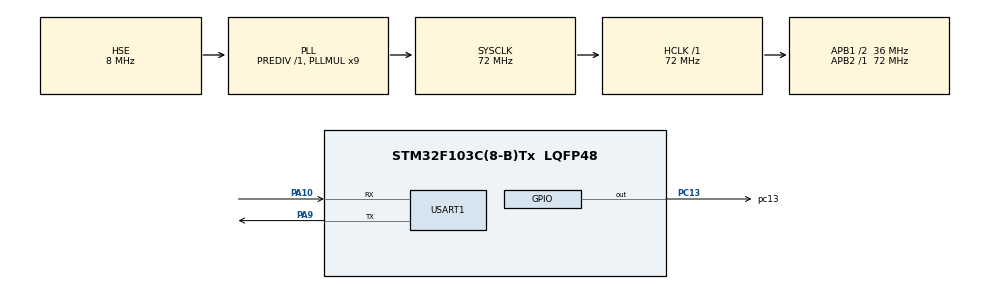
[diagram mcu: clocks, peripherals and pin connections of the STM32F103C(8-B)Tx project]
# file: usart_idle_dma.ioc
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Dma.Request0=USART1_RX
Dma.Request1=USART1_TX
Dma.USART1_RX.0.Direction=DMA_PERIPH_TO_MEMORY
Dma.USART1_RX.0.Instance=DMA1_Channel5
Dma.USART1_RX.0.MemDataAlignment=DMA_MDATAALIGN_BYTE
Dma.USART1_RX.0.MemInc=DMA_MINC_ENABLE
Dma.USART1_RX.0.Mode=DMA_NORMAL
Dma.USART1_RX.0.PeriphDataAlignment=DMA_PDATAALIGN_BYTE
Dma.USART1_RX.0.PeriphInc=DMA_PINC_DISABLE
Dma.USART1_RX.0.Priority=DMA_PRIORITY_LOW
Dma.USART1_TX.1.Direction=DMA_MEMORY_TO_PERIPH
Dma.USART1_TX.1.Instance=DMA1_Channel4
Dma.USART1_TX.1.MemDataAlignment=DMA_MDATAALIGN_BYTE
Dma.USART1_TX.1.MemInc=DMA_MINC_ENABLE
Dma.USART1_TX.1.Mode=DMA_NORMAL
Dma.USART1_TX.1.PeriphDataAlignment=DMA_PDATAALIGN_BYTE
Dma.USART1_TX.1.PeriphInc=DMA_PINC_DISABLE
Dma.USART1_TX.1.Priority=DMA_PRIORITY_LOW
Mcu.Family=STM32F1
Mcu.Name=STM32F103C(8-B)Tx
Mcu.Package=LQFP48
NVIC.DMA1_Channel4_IRQn=true\:0\:0\:false\:false\:true\:false
NVIC.DMA1_Channel5_IRQn=true\:0\:0\:false\:false\:true\:false
NVIC.PriorityGroup=NVIC_PRIORITYGROUP_4
NVIC.USART1_IRQn=true\:0\:0\:false\:false\:true\:true
PA10.Mode=Asynchronous
PA10.Signal=USART1_RX
PA13.Mode=Serial_Wire
PA13.Signal=SYS_JTMS-SWDIO
PA14.Mode=Serial_Wire
PA14.Signal=SYS_JTCK-SWCLK
PA9.Mode=Asynchronous
PA9.Signal=USART1_TX
PC13-TAMPER-RTC.GPIO_Label=pc13
PC13-TAMPER-RTC.Signal=GPIO_Output
PD0-OSC_IN.Mode=HSE-External-Oscillator
PD0-OSC_IN.Signal=RCC_OSC_IN
PD1-OSC_OUT.Mode=HSE-External-Oscillator
PD1-OSC_OUT.Signal=RCC_OSC_OUT
ProjectManager.HeapSize=0x200
ProjectManager.StackSize=0x400
ProjectManager.TargetToolchain=TrueSTUDIO
RCC.AHBFreq_Value=72000000
RCC.APB1CLKDivider=RCC_HCLK_DIV2
RCC.APB1Freq_Value=36000000
RCC.APB1TimFreq_Value=72000000
RCC.APB2Freq_Value=72000000
RCC.APB2TimFreq_Value=72000000
RCC.HCLKFreq_Value=72000000
RCC.PLLMUL=RCC_PLL_MUL9
RCC.PLLSourceVirtual=RCC_PLLSOURCE_HSE
RCC.SYSCLKFreq_VALUE=72000000
RCC.SYSCLKSource=RCC_SYSCLKSOURCE_PLLCLK
RCC.USBFreq_Value=72000000
USART1.VirtualMode=VM_ASYNC
board=custom

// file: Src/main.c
/* USER CODE BEGIN Header */
/**
  ******************************************************************************
  * @file           : main.c
  * @brief          : Main program body
  ******************************************************************************
  ** This notice applies to any and all portions of this file
  * that are not between comment pairs USER CODE BEGIN and
  * USER CODE END. Other portions of this file, whether
  * inserted by the user or by software development tools
  * are owned by their respective copyright owners.
  *
  * COPYRIGHT(c) 2019 STMicroelectronics
  *
  * Redistribution and use in source and binary forms, with or without modification,
  * are permitted provided that the following conditions are met:
  *   1. Redistributions of source code must retain the above copyright notice,
  *      this list of conditions and the following disclaimer.
  *   2. Redistributions in binary form must reproduce the above copyright notice,
  *      this list of conditions and the following disclaimer in the documentation
  *      and/or other materials provided with the distribution.
  *   3. Neither the name of STMicroelectronics nor the names of its contributors
  *      may be used to endorse or promote products derived from this software
  *      without specific prior written permission.
  *
  * THIS SOFTWARE IS PROVIDED BY THE COPYRIGHT HOLDERS AND CONTRIBUTORS "AS IS"
  * AND ANY EXPRESS OR IMPLIED WARRANTIES, INCLUDING, BUT NOT LIMITED TO, THE
  * IMPLIED WARRANTIES OF MERCHANTABILITY AND FITNESS FOR A PARTICULAR PURPOSE ARE
  * DISCLAIMED. IN NO EVENT SHALL THE COPYRIGHT HOLDER OR CONTRIBUTORS BE LIABLE
  * FOR ANY DIRECT, INDIRECT, INCIDENTAL, SPECIAL, EXEMPLARY, OR CONSEQUENTIAL
  * DAMAGES (INCLUDING, BUT NOT LIMITED TO, PROCUREMENT OF SUBSTITUTE GOODS OR
  * SERVICES; LOSS OF USE, DATA, OR PROFITS; OR BUSINESS INTERRUPTION) HOWEVER
  * CAUSED AND ON ANY THEORY OF LIABILITY, WHETHER IN CONTRACT, STRICT LIABILITY,
  * OR TORT (INCLUDING NEGLIGENCE OR OTHERWISE) ARISING IN ANY WAY OUT OF THE USE
  * OF THIS SOFTWARE, EVEN IF ADVISED OF THE POSSIBILITY OF SUCH DAMAGE.
  *
  ******************************************************************************
  */
/* USER CODE END Header */

#include "main.h"

/* USER CODE BEGIN Includes */
#include "string.h"
/* USER CODE END Includes */

/* USER CODE BEGIN PD */
#define BUFSIZE 7 // здесь указать размер буфера нужного размера
/* USER CODE END PD */

UART_HandleTypeDef huart1;
DMA_HandleTypeDef hdma_usart1_rx;
DMA_HandleTypeDef hdma_usart1_tx;

/* USER CODE BEGIN PV */
uint8_t rx_buff[BUFSIZE] = {0,};
uint16_t rx_buff_len;
/* USER CODE END PV */

void SystemClock_Config(void);
static void MX_GPIO_Init(void);
static void MX_DMA_Init(void);
static void MX_USART1_UART_Init(void);

/* USER CODE BEGIN 0 */

/////////////////////////////////////////////////////////////////////////////////////////////////////
////////////////////////////////////////// variant 1 ////////////////////////////////////////////////
/////////////////////////////////////////////////////////////////////////////////////////////////////

/////////////////////////////////// не полный буфер ///////////////////////////////////////
void HAL_UART_IDLE_Callback(UART_HandleTypeDef *huart)
{
	if(huart == &huart1)
	{
		__HAL_UART_DISABLE_IT(&huart1, UART_IT_IDLE);
		rx_buff_len = BUFSIZE - __HAL_DMA_GET_COUNTER(huart->hdmarx);
		//HAL_UART_DMAStop(&huart1);
		uint8_t res = HAL_UART_Transmit_DMA(&huart1, (uint8_t*)rx_buff, rx_buff_len);
		if(res == HAL_ERROR) HAL_UART_Transmit(&huart1, (uint8_t*)"HAL_ERROR - rx_buff == NULL or rx_buff_len == 0\n", 48, 1000);
		else if(res == HAL_BUSY) HAL_UART_Transmit(&huart1, (uint8_t*)"HAL_BUSY\n", 9, 1000);
		HAL_UART_AbortReceive(&huart1);
		__HAL_UART_CLEAR_IDLEFLAG(&huart1);
		__HAL_UART_ENABLE_IT(&huart1, UART_IT_IDLE);
		HAL_UART_Receive_DMA(&huart1, (uint8_t*)rx_buff, BUFSIZE);
	}
}

/////////////////////////////////// полный буфер ///////////////////////////////////////
void HAL_UART_RxCpltCallback(UART_HandleTypeDef *huart)
{
	  if(huart == &huart1)
	  {
		  __HAL_UART_DISABLE_IT(&huart1, UART_IT_IDLE);
		  //HAL_UART_DMAStop(&huart1);
		  HAL_UART_Transmit_DMA(&huart1, (uint8_t*)"Full buffer\n", 12);
		  HAL_UART_AbortReceive(&huart1);
		  __HAL_UART_CLEAR_IDLEFLAG(&huart1);
		  __HAL_UART_ENABLE_IT(&huart1, UART_IT_IDLE);
		  HAL_UART_Receive_DMA(&huart1, (uint8_t*)rx_buff, BUFSIZE);
	  }
}

/////////////////////////////////////////////////////////////////////////////////////////////////////
////////////////////////////////////////// variant 2 ////////////////////////////////////////////////
/////////////////////////////////////////////////////////////////////////////////////////////////////
/*
void HAL_UART_TxCpltCallback(UART_HandleTypeDef *huart)
{
	if(huart == &huart1)
	{
		HAL_UART_AbortReceive(&huart1);
		//HAL_UART_DMAStop(&huart1);
		__HAL_UART_ENABLE_IT(&huart1, UART_IT_IDLE);
		__HAL_UART_CLEAR_IDLEFLAG(&huart1);
		HAL_UART_Receive_DMA(&huart1, (uint8_t*)rx_buff, BUFSIZE);
	}
}

/////////////////////////////////// не полный буфер ///////////////////////////////////////
void HAL_UART_IDLE_Callback(UART_HandleTypeDef *huart)
{
	if(huart == &huart1)
	{
		__HAL_UART_DISABLE_IT(huart, UART_IT_IDLE);
		rx_buff_len = BUFSIZE - __HAL_DMA_GET_COUNTER(huart->hdmarx);
		HAL_UART_AbortTransmit(&huart1);
		//HAL_UART_DMAStop(&huart1);
		uint8_t res = HAL_UART_Transmit_DMA(&huart1, (uint8_t*)rx_buff, rx_buff_len);
		if(res == HAL_ERROR) HAL_UART_Transmit(&huart1, (uint8_t*)"HAL_ERROR - rx_buff == NULL or rx_buff_len == 0\n", 48, 1000);
		else if(res == HAL_BUSY) HAL_UART_Transmit(&huart1, (uint8_t*)"HAL_BUSY\n", 9, 1000);
	}
}

/////////////////////////////////// полный буфер ///////////////////////////////////////
void HAL_UART_RxCpltCallback(UART_HandleTypeDef *huart)
{
	  if(huart == &huart1)
	  {
		  __HAL_UART_DISABLE_IT(&huart1, UART_IT_IDLE);
		  HAL_UART_Transmit_DMA(&huart1, (uint8_t*)"Full buffer\n", 12);
	  }
}
*/
///////////////////////////////////////////////////////////////////////////////////////////////////////////////////
////////////////////////////////////////////// ErrorCallback //////////////////////////////////////////////////////
///////////////////////////////////////////////////////////////////////////////////////////////////////////////////

void HAL_UART_ErrorCallback(UART_HandleTypeDef *huart)
{
	if(huart == &huart1)
	{
		__HAL_UART_DISABLE_IT(&huart1, UART_IT_IDLE);
		HAL_UART_DMAStop(&huart1);
		HAL_GPIO_TogglePin(pc13_GPIO_Port, pc13_Pin);
		uint32_t er = HAL_UART_GetError(&huart1);

		switch(er)
		{
			case HAL_UART_ERROR_PE:
				HAL_UART_Transmit(&huart1, (uint8_t*)"ERR_Callbck - Parity error\n", 27, 1000);
				__HAL_UART_CLEAR_PEFLAG(&huart1);
				huart->ErrorCode = HAL_UART_ERROR_NONE;
			break;

			case HAL_UART_ERROR_NE:
				HAL_UART_Transmit(&huart1, (uint8_t*)"ERR_Callbck - Noise error\n", 26, 1000);
				__HAL_UART_CLEAR_NEFLAG(&huart1);
				huart->ErrorCode = HAL_UART_ERROR_NONE;
			break;

			case HAL_UART_ERROR_FE:
				HAL_UART_Transmit(&huart1, (uint8_t*)"ERR_Callbck - Frame error\n", 26, 1000);
				__HAL_UART_CLEAR_FEFLAG(&huart1);
				huart->ErrorCode = HAL_UART_ERROR_NONE;
			break;

			case HAL_UART_ERROR_ORE:
				HAL_UART_Transmit(&huart1, (uint8_t*)"ERR_Callbck - Overrun error\n", 28, 1000);
				__HAL_UART_CLEAR_OREFLAG(huart);
				huart->ErrorCode = HAL_UART_ERROR_NONE;
			break;

			case HAL_UART_ERROR_DMA:
				HAL_UART_Transmit(&huart1, (uint8_t*)"ERR_Callbck - DMA transfer error\n", 33, 1000);
				huart->ErrorCode = HAL_UART_ERROR_NONE;
			break;

			default:
			break;
		}
	}

}
/* USER CODE END 0 */

int main(void)
{

  /* MCU Configuration--------------------------------------------------------*/

  /* Reset of all peripherals, Initializes the Flash interface and the Systick. */
  HAL_Init();

  /* Configure the system clock */
  SystemClock_Config();

  /* Initialize all configured peripherals */
  MX_GPIO_Init();
  MX_DMA_Init();
  MX_USART1_UART_Init();
  /* USER CODE BEGIN 2 */
  __HAL_UART_ENABLE_IT(&huart1, UART_IT_IDLE);
  HAL_UART_Receive_DMA(&huart1, (uint8_t*)rx_buff, BUFSIZE);

  HAL_GPIO_WritePin(pc13_GPIO_Port, pc13_Pin, GPIO_PIN_SET);
  /* USER CODE END 2 */

  /* Infinite loop */
  while (1)
  {

  }
}

void SystemClock_Config(void)
{
  RCC_OscInitTypeDef RCC_OscInitStruct = {0};
  RCC_ClkInitTypeDef RCC_ClkInitStruct = {0};

  /**Initializes the CPU, AHB and APB busses clocks
  */
  RCC_OscInitStruct.OscillatorType = RCC_OSCILLATORTYPE_HSE;
  RCC_OscInitStruct.HSEState = RCC_HSE_ON;
  RCC_OscInitStruct.HSEPredivValue = RCC_HSE_PREDIV_DIV1;
  RCC_OscInitStruct.HSIState = RCC_HSI_ON;
  RCC_OscInitStruct.PLL.PLLState = RCC_PLL_ON;
  RCC_OscInitStruct.PLL.PLLSource = RCC_PLLSOURCE_HSE;
  RCC_OscInitStruct.PLL.PLLMUL = RCC_PLL_MUL9;
  if (HAL_RCC_OscConfig(&RCC_OscInitStruct) != HAL_OK)
  {
    Error_Handler();
  }
  /**Initializes the CPU, AHB and APB busses clocks
  */
  RCC_ClkInitStruct.ClockType = RCC_CLOCKTYPE_HCLK|RCC_CLOCKTYPE_SYSCLK
                              |RCC_CLOCKTYPE_PCLK1|RCC_CLOCKTYPE_PCLK2;
  RCC_ClkInitStruct.SYSCLKSource = RCC_SYSCLKSOURCE_PLLCLK;
  RCC_ClkInitStruct.AHBCLKDivider = RCC_SYSCLK_DIV1;
  RCC_ClkInitStruct.APB1CLKDivider = RCC_HCLK_DIV2;
  RCC_ClkInitStruct.APB2CLKDivider = RCC_HCLK_DIV1;

  if (HAL_RCC_ClockConfig(&RCC_ClkInitStruct, FLASH_LATENCY_2) != HAL_OK)
  {
    Error_Handler();
  }
}

static void MX_USART1_UART_Init(void)
{

  huart1.Instance = USART1;
  huart1.Init.BaudRate = 115200;
  huart1.Init.WordLength = UART_WORDLENGTH_8B;
  huart1.Init.StopBits = UART_STOPBITS_1;
  huart1.Init.Parity = UART_PARITY_NONE;
  huart1.Init.Mode = UART_MODE_TX_RX;
  huart1.Init.HwFlowCtl = UART_HWCONTROL_NONE;
  huart1.Init.OverSampling = UART_OVERSAMPLING_16;
  if (HAL_UART_Init(&huart1) != HAL_OK)
  {
    Error_Handler();
  }

}

static void MX_DMA_Init(void)
{
  /* DMA controller clock enable */
  __HAL_RCC_DMA1_CLK_ENABLE();

  /* DMA interrupt init */
  /* DMA1_Channel4_IRQn interrupt configuration */
  HAL_NVIC_SetPriority(DMA1_Channel4_IRQn, 0, 0);
  HAL_NVIC_EnableIRQ(DMA1_Channel4_IRQn);
  /* DMA1_Channel5_IRQn interrupt configuration */
  HAL_NVIC_SetPriority(DMA1_Channel5_IRQn, 0, 0);
  HAL_NVIC_EnableIRQ(DMA1_Channel5_IRQn);

}

static void MX_GPIO_Init(void)
{
  GPIO_InitTypeDef GPIO_InitStruct = {0};

  /* GPIO Ports Clock Enable */
  __HAL_RCC_GPIOC_CLK_ENABLE();
  __HAL_RCC_GPIOD_CLK_ENABLE();
  __HAL_RCC_GPIOA_CLK_ENABLE();

  /*Configure GPIO pin Output Level */
  HAL_GPIO_WritePin(pc13_GPIO_Port, pc13_Pin, GPIO_PIN_RESET);

  /*Configure GPIO pin : pc13_Pin */
  GPIO_InitStruct.Pin = pc13_Pin;
  GPIO_InitStruct.Mode = GPIO_MODE_OUTPUT_PP;
  GPIO_InitStruct.Pull = GPIO_NOPULL;
  GPIO_InitStruct.Speed = GPIO_SPEED_FREQ_LOW;
  HAL_GPIO_Init(pc13_GPIO_Port, &GPIO_InitStruct);

}

void Error_Handler(void)
{
}

/************************ (C) COPYRIGHT STMicroelectronics *****END OF FILE****/
